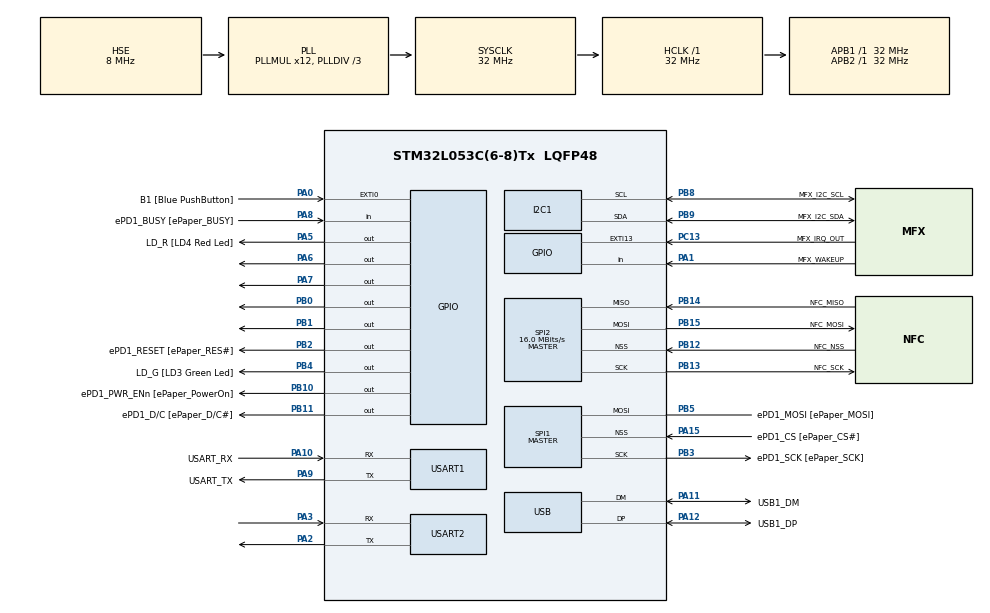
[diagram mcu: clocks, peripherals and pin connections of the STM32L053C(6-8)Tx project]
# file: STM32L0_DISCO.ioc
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Mcu.Family=STM32L0
Mcu.Name=STM32L053C(6-8)Tx
Mcu.Package=LQFP48
PA0.GPIO_Label=B1 [Blue PushButton]
PA0.GPIO_ModeDefaultEXTI=GPIO_MODE_EVT_RISING
PA0.GPIO_PuPd=GPIO_NOPULL
PA0.Signal=GPXTI0
PA1.GPIO_Label=MFX_WAKEUP
PA1.Signal=GPIO_Input
PA10.GPIO_Label=USART_RX
PA10.Mode=Asynchronous
PA10.Signal=USART1_RX
PA11.GPIO_Label=USB1_DM
PA11.Mode=Device
PA11.Signal=USB_DM
PA12.GPIO_Label=USB1_DP
PA12.Mode=Device
PA12.Signal=USB_DP
PA13.GPIO_Label=SWDIO
PA13.Mode=Serial_Wire
PA13.Signal=SYS_SWDIO
PA14.GPIO_Label=SWCLK
PA14.Mode=Serial_Wire
PA14.Signal=SYS_SWCLK
PA15.GPIO_Label=ePD1_CS [ePaper_CS\#]
PA15.GPIO_Mode=GPIO_MODE_AF_PP
PA15.GPIO_PuPd=GPIO_NOPULL
PA15.GPIO_Speed=GPIO_SPEED_FREQ_LOW
PA15.Mode=NSS_Signal_Hard_Input
PA15.Signal=SPI1_NSS
PA2.Mode=Asynchronous
PA2.Signal=USART2_TX
PA3.Mode=Asynchronous
PA3.Signal=USART2_RX
PA5.GPIO_Label=LD_R [LD4 Red Led]
PA5.GPIO_ModeDefaultOutputPP=GPIO_MODE_OUTPUT_PP
PA5.GPIO_PuPd=GPIO_NOPULL
PA5.GPIO_Speed=GPIO_SPEED_FREQ_LOW
PA5.Signal=GPIO_Output
PA6.Signal=SharedStack_PA6
PA6.Stacked=true
PA7.Signal=GPIO_Output
PA8.GPIO_Label=ePD1_BUSY [ePaper_BUSY]
PA8.GPIO_Mode=GPIO_MODE_INPUT
PA8.GPIO_PuPd=GPIO_NOPULL
PA8.Signal=GPIO_Input
PA9.GPIO_Label=USART_TX
PA9.Mode=Asynchronous
PA9.Signal=USART1_TX
PB0.Signal=GPIO_Output
PB1.Signal=GPIO_Output
PB10.GPIO_Label=ePD1_PWR_ENn [ePaper_PowerOn]
PB10.GPIO_ModeDefaultOutputPP=GPIO_MODE_OUTPUT_PP
PB10.GPIO_PuPd=GPIO_NOPULL
PB10.GPIO_Speed=GPIO_SPEED_FREQ_LOW
PB10.Signal=GPIO_Output
PB11.GPIO_Label=ePD1_D/C [ePaper_D/C\#]
PB11.GPIO_ModeDefaultOutputPP=GPIO_MODE_OUTPUT_PP
PB11.GPIO_PuPd=GPIO_NOPULL
PB11.GPIO_Speed=GPIO_SPEED_FREQ_LOW
PB11.Signal=GPIO_Output
PB12.GPIO_Label=NFC_NSS
PB12.Mode=NSS_Signal_Hard_Input
PB12.Signal=SPI2_NSS
PB13.GPIO_Label=NFC_SCK
PB13.Mode=Full_Duplex_Master
PB13.Signal=SPI2_SCK
PB14.GPIO_Label=NFC_MISO
PB14.Mode=Full_Duplex_Master
PB14.Signal=SPI2_MISO
PB15.GPIO_Label=NFC_MOSI
PB15.Mode=Full_Duplex_Master
PB15.Signal=SPI2_MOSI
PB2.GPIO_Label=ePD1_RESET [ePaper_RES\#]
PB2.GPIO_ModeDefaultOutputPP=GPIO_MODE_OUTPUT_PP
PB2.GPIO_PuPd=GPIO_NOPULL
PB2.GPIO_Speed=GPIO_SPEED_FREQ_LOW
PB2.Signal=GPIO_Output
PB3.GPIO_Label=ePD1_SCK [ePaper_SCK]
PB3.GPIO_Mode=GPIO_MODE_AF_PP
PB3.GPIO_PuPd=GPIO_NOPULL
PB3.GPIO_Speed=GPIO_SPEED_FREQ_LOW
PB3.Mode=Simplex_Bidirectional_Master
PB3.Signal=SPI1_SCK
PB4.GPIO_Label=LD_G [LD3 Green Led]
PB4.GPIO_ModeDefaultOutputPP=GPIO_MODE_OUTPUT_PP
PB4.GPIO_PuPd=GPIO_NOPULL
PB4.GPIO_Speed=GPIO_SPEED_FREQ_LOW
PB4.Signal=GPIO_Output
PB5.GPIO_Label=ePD1_MOSI [ePaper_MOSI]
PB5.GPIO_Mode=GPIO_MODE_AF_PP
PB5.GPIO_PuPd=GPIO_NOPULL
PB5.GPIO_Speed=GPIO_SPEED_FREQ_LOW
PB5.Mode=Simplex_Bidirectional_Master
PB5.Signal=SPI1_MOSI
PB8.GPIO_Label=MFX_I2C_SCL
PB8.Mode=I2C
PB8.Signal=I2C1_SCL
PB9.GPIO_Label=MFX_I2C_SDA
PB9.Mode=I2C
PB9.Signal=I2C1_SDA
PC13.GPIO_Label=MFX_IRQ_OUT
PC13.Signal=GPXTI13
PC14-OSC32_IN.GPIO_Label=PC14-OSC32_IN
PC14-OSC32_IN.Signal=RCC_OSC32_IN
PC15-OSC32_OUT.GPIO_Label=PC15-OSC32_OUT
PC15-OSC32_OUT.Signal=RCC_OSC32_OUT
PH0-OSC_IN.GPIO_Label=MCO
PH0-OSC_IN.Mode=HSE-External-Clock-Source
PH0-OSC_IN.Signal=RCC_OSC_IN
ProjectManager.HeapSize=0x200
ProjectManager.StackSize=0x400
ProjectManager.TargetToolchain=TrueSTUDIO
RCC.AHBFreq_Value=32000000
RCC.APB1Freq_Value=32000000
RCC.APB1TimFreq_Value=32000000
RCC.APB2Freq_Value=32000000
RCC.APB2TimFreq_Value=32000000
RCC.HCLKFreq_Value=32000000
RCC.HSE_VALUE=8000000
RCC.HSI16_VALUE=16000000
RCC.HSI48MClockSelection=RCC_USBCLKSOURCE_HSI48
RCC.HSI48_VALUE=48000000
RCC.HSI_VALUE=16000000
RCC.LSE_VALUE=32768
RCC.MSI_VALUE=2097000
RCC.PLLDIV=RCC_PLLDIV_3
RCC.PLLMUL=RCC_PLLMUL_12
RCC.PLLSourceVirtual=RCC_PLLSOURCE_HSE
RCC.RTCClockSelectionVirtual=RCC_RTCCLKSOURCE_LSE
RCC.SYSCLKFreq_VALUE=32000000
RCC.SYSCLKSource=RCC_SYSCLKSOURCE_PLLCLK
RCC.VCOOutputFreq_Value=96000000
SH.SharedStack_PA6.0=TSC_G2_IO3
SH.SharedStack_PA6.1=GPIO_Output
SPI1.CalculateBaudRate-Simplex_Bidirectional_Master=16.0 MBits/s
SPI1.Direction=SPI_DIRECTION_1LINE
SPI1.Direction-Simplex_Bidirectional_Master=SPI_DIRECTION_1LINE
SPI1.Mode=SPI_MODE_MASTER
SPI1.Mode-Simplex_Bidirectional_Master=SPI_MODE_MASTER
SPI1.NSS-Simplex_Bidirectional_Master=SPI_NSS_HARD_OUTPUT
SPI1.TIMode-Simplex_Bidirectional_Master=SPI_TIMODE_DISABLE
SPI1.VirtualNSS=VM_NSSHARD
SPI1.VirtualType=VM_MASTER
SPI2.CalculateBaudRate=16.0 MBits/s
SPI2.Direction=SPI_DIRECTION_2LINES
SPI2.Mode=SPI_MODE_MASTER
SPI2.VirtualNSS=VM_NSSHARD
SPI2.VirtualType=VM_MASTER
USART1.VirtualMode-Asynchronous=VM_ASYNC
USART1.WordLength=WORDLENGTH_8B
USART2.VirtualMode-Asynchronous=VM_ASYNC
USART2.WordLength=WORDLENGTH_8B
board=32L0538DISCOVERY

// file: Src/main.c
/**
 ******************************************************************************
 * @file           : main.c
 * @brief          : Main program body
 ******************************************************************************
 ** This notice applies to any and all portions of this file
 * that are not between comment pairs USER CODE BEGIN and
 * USER CODE END. Other portions of this file, whether
 * inserted by the user or by software development tools
 * are owned by their respective copyright owners.
 *
 * COPYRIGHT(c) 2018 STMicroelectronics
 *
 * Redistribution and use in source and binary forms, with or without modification,
 * are permitted provided that the following conditions are met:
 *   1. Redistributions of source code must retain the above copyright notice,
 *      this list of conditions and the following disclaimer.
 *   2. Redistributions in binary form must reproduce the above copyright notice,
 *      this list of conditions and the following disclaimer in the documentation
 *      and/or other materials provided with the distribution.
 *   3. Neither the name of STMicroelectronics nor the names of its contributors
 *      may be used to endorse or promote products derived from this software
 *      without specific prior written permission.
 *
 * THIS SOFTWARE IS PROVIDED BY THE COPYRIGHT HOLDERS AND CONTRIBUTORS "AS IS"
 * AND ANY EXPRESS OR IMPLIED WARRANTIES, INCLUDING, BUT NOT LIMITED TO, THE
 * IMPLIED WARRANTIES OF MERCHANTABILITY AND FITNESS FOR A PARTICULAR PURPOSE ARE
 * DISCLAIMED. IN NO EVENT SHALL THE COPYRIGHT HOLDER OR CONTRIBUTORS BE LIABLE
 * FOR ANY DIRECT, INDIRECT, INCIDENTAL, SPECIAL, EXEMPLARY, OR CONSEQUENTIAL
 * DAMAGES (INCLUDING, BUT NOT LIMITED TO, PROCUREMENT OF SUBSTITUTE GOODS OR
 * SERVICES; LOSS OF USE, DATA, OR PROFITS; OR BUSINESS INTERRUPTION) HOWEVER
 * CAUSED AND ON ANY THEORY OF LIABILITY, WHETHER IN CONTRACT, STRICT LIABILITY,
 * OR TORT (INCLUDING NEGLIGENCE OR OTHERWISE) ARISING IN ANY WAY OUT OF THE USE
 * OF THIS SOFTWARE, EVEN IF ADVISED OF THE POSSIBILITY OF SUCH DAMAGE.
 *
 ******************************************************************************
 */
#include "main.h"
#include "stm32l0xx_hal.h"
#include "i2c.h"
#include "spi.h"
#include "usart.h"
#include "usb.h"
#include "gpio.h"

/* USER CODE BEGIN Includes */
#include "UART_IRQ/UART_IRQ.h"
/* USER CODE END Includes */

/* USER CODE BEGIN PV */
/* Private variables ---------------------------------------------------------*/

/* USER CODE END PV */

void SystemClock_Config(void);

/* USER CODE BEGIN PFP */
/* Private function prototypes -----------------------------------------------*/

/* USER CODE END PFP */

int main(void) {

	/* MCU Configuration----------------------------------------------------------*/

	/* Reset of all peripherals, Initializes the Flash interface and the Systick. */
	HAL_Init();

	/* Configure the system clock */
	SystemClock_Config();

	/* Initialize all configured peripherals */
	MX_GPIO_Init();
	MX_I2C1_Init();
	MX_SPI1_Init();
	MX_SPI2_Init();
	MX_USART1_UART_Init();
	MX_USB_PCD_Init();
	MX_USART2_UART_Init();

	/* Infinite loop */
	/* USER CODE BEGIN WHILE */
	char buf[100] = {};
	while (1) {

		/* USER CODE END WHILE */

		/* USER CODE BEGIN 3 */

		HAL_GPIO_TogglePin(LD_G_GPIO_Port, LD_G_Pin);
		HAL_GPIO_TogglePin(LD_R_GPIO_Port, LD_R_Pin);

		sprintf(buf, "Test\r\n");
		putS(&huart1, buf);
		HAL_Delay(500);
	}
	/* USER CODE END 3 */

}

void SystemClock_Config(void) {

	RCC_OscInitTypeDef RCC_OscInitStruct;
	RCC_ClkInitTypeDef RCC_ClkInitStruct;
	RCC_PeriphCLKInitTypeDef PeriphClkInit;

	/**Configure the main internal regulator output voltage
	 */
	__HAL_PWR_VOLTAGESCALING_CONFIG(PWR_REGULATOR_VOLTAGE_SCALE1);

	/**Initializes the CPU, AHB and APB busses clocks
	 */
	RCC_OscInitStruct.OscillatorType = RCC_OSCILLATORTYPE_HSE
			| RCC_OSCILLATORTYPE_HSI48;
	RCC_OscInitStruct.HSEState = RCC_HSE_BYPASS;
	RCC_OscInitStruct.HSI48State = RCC_HSI48_ON;
	RCC_OscInitStruct.PLL.PLLState = RCC_PLL_ON;
	RCC_OscInitStruct.PLL.PLLSource = RCC_PLLSOURCE_HSE;
	RCC_OscInitStruct.PLL.PLLMUL = RCC_PLLMUL_12;
	RCC_OscInitStruct.PLL.PLLDIV = RCC_PLLDIV_3;
	if (HAL_RCC_OscConfig(&RCC_OscInitStruct) != HAL_OK) {
		_Error_Handler(__FILE__, __LINE__);
	}

	/**Initializes the CPU, AHB and APB busses clocks
	 */
	RCC_ClkInitStruct.ClockType = RCC_CLOCKTYPE_HCLK | RCC_CLOCKTYPE_SYSCLK
			| RCC_CLOCKTYPE_PCLK1 | RCC_CLOCKTYPE_PCLK2;
	RCC_ClkInitStruct.SYSCLKSource = RCC_SYSCLKSOURCE_PLLCLK;
	RCC_ClkInitStruct.AHBCLKDivider = RCC_SYSCLK_DIV1;
	RCC_ClkInitStruct.APB1CLKDivider = RCC_HCLK_DIV1;
	RCC_ClkInitStruct.APB2CLKDivider = RCC_HCLK_DIV1;

	if (HAL_RCC_ClockConfig(&RCC_ClkInitStruct, FLASH_LATENCY_1) != HAL_OK) {
		_Error_Handler(__FILE__, __LINE__);
	}

	PeriphClkInit.PeriphClockSelection = RCC_PERIPHCLK_USART1
			| RCC_PERIPHCLK_USART2 | RCC_PERIPHCLK_I2C1 | RCC_PERIPHCLK_USB;
	PeriphClkInit.Usart1ClockSelection = RCC_USART1CLKSOURCE_PCLK2;
	PeriphClkInit.Usart2ClockSelection = RCC_USART2CLKSOURCE_PCLK1;
	PeriphClkInit.I2c1ClockSelection = RCC_I2C1CLKSOURCE_PCLK1;
	PeriphClkInit.UsbClockSelection = RCC_USBCLKSOURCE_HSI48;
	if (HAL_RCCEx_PeriphCLKConfig(&PeriphClkInit) != HAL_OK) {
		_Error_Handler(__FILE__, __LINE__);
	}

	/**Configure the Systick interrupt time
	 */
	HAL_SYSTICK_Config(HAL_RCC_GetHCLKFreq() / 1000);

	/**Configure the Systick
	 */
	HAL_SYSTICK_CLKSourceConfig(SYSTICK_CLKSOURCE_HCLK);

	/* SysTick_IRQn interrupt configuration */
	HAL_NVIC_SetPriority(SysTick_IRQn, 0, 0);
}

void _Error_Handler(char *file, int line) {
	while (1) {
	}
}

/************************ (C) COPYRIGHT STMicroelectronics *****END OF FILE****/
